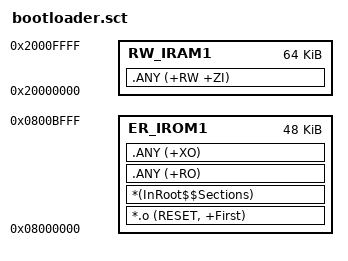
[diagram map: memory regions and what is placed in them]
; *************************************************************
; ***          Bootloader Scatter Load Description           ***
; ***  STM32F103VE 512KB Flash / 64KB RAM                   ***
; ***  Bootloader: 0x08000000 ~ 0x0800BFFF (48KB)           ***
; ***  App:        0x08010000 ~ 0x08057FFF (288KB)          ***
; ***  参数区:      0x08058000 ~ 0x0806FFFF (96KB)            ***
; *************************************************************

LR_IROM1 0x08000000 0x0000C000  {    ; 48KB Bootloader
  ER_IROM1 0x08000000 0x0000C000  {  ; code + RO data
   *.o (RESET, +First)
   *(InRoot$$Sections)
   .ANY (+RO)
   .ANY (+XO)
  }
  RW_IRAM1 0x20000000 0x00010000  {  ; 64KB RAM
   .ANY (+RW +ZI)
  }
}
